# AT32F402xx_v2 register map
Vendor: Keil; Series: AT32F402; File version: 1.0
CPU: CM4 r0p1, little endian, no MPU, FPU, 4 interrupt priority bits
Registers are 32-bit, read-write, reset 0x0 unless marked. A register's access mark holds for its fields unless they carry their own. Offsets are from the block's base; [hi:lo] are bit positions.

## ACC — HSI Auto Clock Calibration
Base 0x40017400
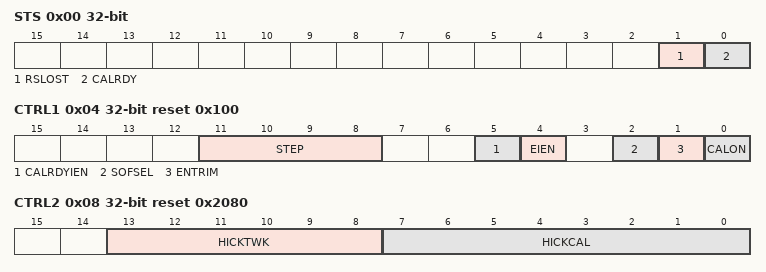
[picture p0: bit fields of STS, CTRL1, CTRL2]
0x00 STS — status register
  [1] RSLOST — Reference Signal Lost
  [0] CALRDY — Internal high-speed clock calibration ready
0x04 CTRL1 reset 0x100 — control register 1
  [11:8] STEP
  [5] CALRDYIEN — CALRDY interrupt enable
  [4] EIEN — RSLOST error interrupt enable
  [2] SOFSEL — SOF Select
  [1] ENTRIM — Enable trim
  [0] CALON — Calibration on
0x08 CTRL2 reset 0x2080 — control register 2
  [13:8] HICKTWK ro — Internal high-speed auto clock trimming
  [7:0] HICKCAL ro — Internal high-speed auto clock calibration
0x0C C1 reset 0x1F2C — compare value 1
  [15:0] C1 — Compare 1
0x10 C2 reset 0x1F40 — compare value 2
  [15:0] C2 — Compare 2
0x14 C3 reset 0x1F54 — compare value 3
  [15:0] C3 — Compare 3

## SPI1 — Serial peripheral interface
Base 0x40013000
Same registers: SPI2 0x40003800, SPI3 0x40003C00
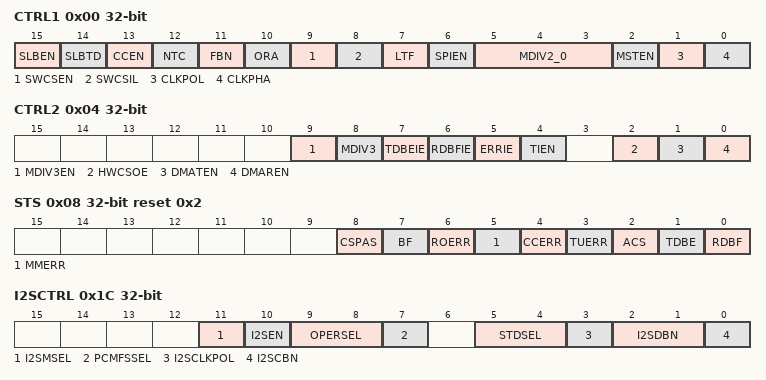
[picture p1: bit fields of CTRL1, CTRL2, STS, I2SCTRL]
0x00 CTRL1 — control register 1
  [15] SLBEN — Single line bidirectional half-duplex enable
  [14] SLBTD — Single line bidirectional half-duplex transmission direction
  [13] CCEN — CRC calculation enable
  [12] NTC — Next transmission CRC
  [11] FBN — frame bit num
  [10] ORA — Only receive active
  [9] SWCSEN — Software CS enable
  [8] SWCSIL — Software CS internal level
  [7] LTF — LSB transmit first
  [6] SPIEN — SPI enable
  [5:3] MDIV2_0 — Master clock frequency division bit2-0
  [2] MSTEN — Master enable
  [1] CLKPOL — Clock polarity
  [0] CLKPHA — Clock phase
0x04 CTRL2 — control register 2
  [9] MDIV3EN — Master clock frequency3 division enable
  [8] MDIV3 — Master clock frequency division bit3
  [7] TDBEIE — Transmit data buffer empty interrupt enable
  [6] RDBFIE — Receive data buffer full interrupt enable
  [5] ERRIE — Error interrupt enable
  [4] TIEN — TI mode enable
  [2] HWCSOE — Hardware CS output enable
  [1] DMATEN — DMA transmit enable
  [0] DMAREN — DMA receive enable
0x08 STS reset 0x2 — status register
  [8] CSPAS — CS pulse abnormal setting fiag
  [7] BF ro — Busy flag
  [6] ROERR ro — Receiver overflow error
  [5] MMERR ro — Master mode error
  [4] CCERR — CRC calculation error
  [3] TUERR ro — Transmitter underload error
  [2] ACS ro — Audio channel state
  [1] TDBE ro — Transmit data buffer empty
  [0] RDBF ro — Receive data buffer full
0x0C DT — data register
  [15:0] DT — Data value
0x10 CPOLY reset 0x7 — CRC polynomial register
  [15:0] CPOLY — CRC polynomial
0x14 RCRC ro — Receive CRC register
  [15:0] RCRC — Receive CRC
0x18 TCRC ro — Transmit CRC register
  [15:0] TCRC — Transmit CRC
0x1C I2SCTRL — I2S control register
  [11] I2SMSEL — I2S mode select
  [10] I2SEN — I2S Enable
  [9:8] OPERSEL — I2S operation select
  [7] PCMFSSEL — PCM frame synchronization select
  [5:4] STDSEL — I2S standard select
  [3] I2SCLKPOL — I2S clock polarity
  [2:1] I2SDBN — I2S data bit num
  [0] I2SCBN — I2S channel bit num
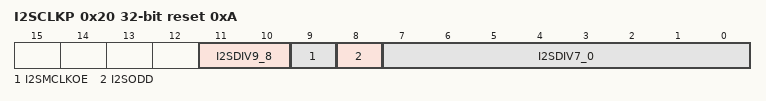
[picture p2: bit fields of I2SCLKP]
0x20 I2SCLKP reset 0xA — I2S clock register
  [11:10] I2SDIV9_8 — I2S division bit9 and bit8
  [9] I2SMCLKOE — I2S master clock output enable
  [8] I2SODD — Odd result for I2S division
  [7:0] I2SDIV7_0 — I2S division bit7 to bit0

## I2SF5 — Serial peripheral interface
Base 0x40015000
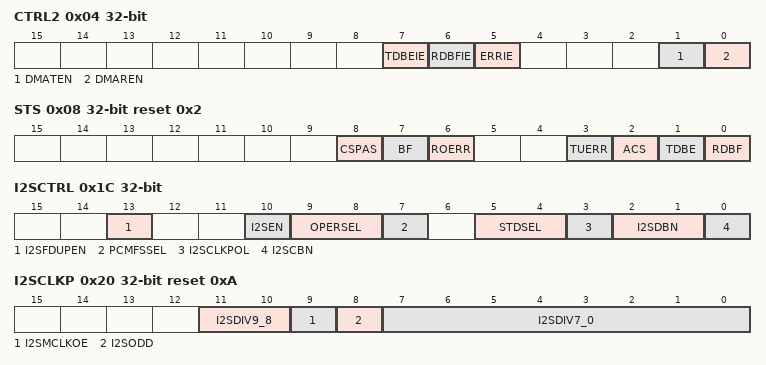
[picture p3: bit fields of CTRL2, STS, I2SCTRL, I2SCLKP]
0x04 CTRL2 — control register 2
  [7] TDBEIE — Transmit data buffer empty interrupt enable
  [6] RDBFIE — Receive data buffer full interrupt enable
  [5] ERRIE — Error interrupt enable
  [1] DMATEN — DMA transmit enable
  [0] DMAREN — DMA receive enable
0x08 STS reset 0x2 — status register
  [8] CSPAS — CS pulse abnormal setting fiag
  [7] BF ro — Busy flag
  [6] ROERR ro — Receiver overflow error
  [3] TUERR ro — Transmitter underload error
  [2] ACS ro — Audio channel state
  [1] TDBE ro — Transmit data buffer empty
  [0] RDBF ro — Receive data buffer full
0x0C DT — data register
  [15:0] DT — Data value
0x1C I2SCTRL — I2S control register
  [13] I2SFDUPEN — I2S full duplex mode enable
  [10] I2SEN — I2S Enable
  [9:8] OPERSEL — I2S operation select
  [7] PCMFSSEL — PCM frame synchronization select
  [5:4] STDSEL — I2S standard select
  [3] I2SCLKPOL — I2S clock polarity
  [2:1] I2SDBN — I2S data bit num
  [0] I2SCBN — I2S channel bit num
0x20 I2SCLKP reset 0xA — I2S clock register
  [11:10] I2SDIV9_8 — I2S division bit9 and bit8
  [9] I2SMCLKOE — I2S master clock output enable
  [8] I2SODD — Odd result for I2S division
  [7:0] I2SDIV7_0 — I2S division bit7 to bit0
0x30 MISC1
  [0] I2SPCMCKSEL — I2S PCM clock edge select
